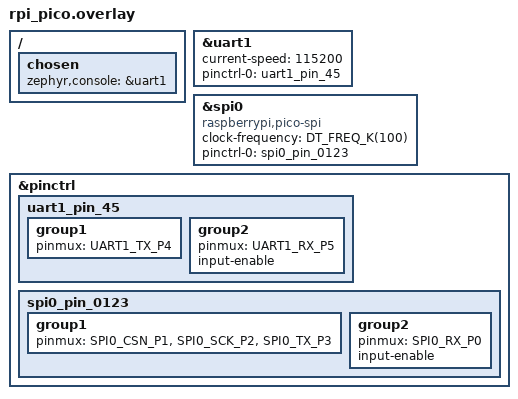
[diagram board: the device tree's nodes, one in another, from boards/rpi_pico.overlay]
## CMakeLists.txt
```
cmake_minimum_required(VERSION 3.20.0)
find_package(Zephyr REQUIRED HINTS $ENV{ZEPHYR_BASE})
project(Car_OS_Zephyr)


set(CMAKE_VERBOSE_MAKEFILE TRUE)

# The default app target from Zephyr
target_sources(app PRIVATE src/main.c)



include(${CMAKE_CURRENT_SOURCE_DIR}/car-os/path_defs.cmake)
#######################################################################################################
# Implementation as per the link below:
# https://github.com/zephyrproject-rtos/zephyr/tree/main/samples/application_development/external_lib
#######################################################################################################
# The external static library that we are linking with (i.e., libCar_OS) does not know how to build for
# this platform. So we export all the flags used in this zephyr build to the external build system.
#
# Other external build systems may be self-contained enough that they do not need any build information
# from zephyr. Or they may be incompatible with certain zephyr options and need them to be filtered out
zephyr_get_include_directories_for_lang_as_string(
  C includes
)
zephyr_get_system_include_directories_for_lang_as_string(
  C system_includes
)
zephyr_get_compile_definitions_for_lang_as_string(
  C definitions
)
zephyr_get_compile_options_for_lang_as_string(
  C options
)

set(
  external_project_cflags
  "${includes} ${definitions} ${options} ${system_includes}"
)

include(ExternalProject)


# Add an external project to be able download and build the third
# party library. In this case downloading is not necessary as it has
# been committed to the repository.
set(CAR_OS_SRC_DIR   ${CMAKE_CURRENT_SOURCE_DIR}/car-os)
set(CAR_OS_BUILD_DIR ${CMAKE_CURRENT_BINARY_DIR}/car-os)
set(CAR_OS_INCLUDE_DIR ${CAR_OS_SRC_DIR}/include)

if(CMAKE_GENERATOR STREQUAL "Unix Makefiles")
  # https://www.gnu.org/software/make/manual/html_node/MAKE-Variable.html
  set(submake "$(MAKE)")
else() # Obviously no MAKEFLAGS. Let's hope a "make" can be found somewhere.
  set(submake "make")
endif()


ExternalProject_Add(
  Car_OS_project                 # Name for custom target
  PREFIX     ${CAR_OS_BUILD_DIR} # Root dir for entire project
  SOURCE_DIR ${CAR_OS_SRC_DIR}
  BINARY_DIR ${CAR_OS_SRC_DIR}   # This particular build system is invoked from the root
  CONFIGURE_COMMAND ""           # Skip configuring the project, e.g. with autoconf
  BUILD_COMMAND ${submake}
  PREFIX=${CAR_OS_BUILD_DIR}
  CC=${CMAKE_C_COMPILER}
  AR=${CMAKE_AR}
  CFLAGS=${external_project_cflags}
  INSTALL_COMMAND ""             # This particular build system has no install command
  BUILD_BYPRODUCTS ${CAR_OS_BASE_DIR_PATH}/libCar_OS.a
  DEPENDS zephyr_interface
)


# Create a wrapper CMake library that our app can link with
add_library(Car_OS_lib STATIC IMPORTED GLOBAL)
add_dependencies(
  Car_OS_lib
  Car_OS_project
)
set_target_properties(Car_OS_lib PROPERTIES IMPORTED_LOCATION             ${CAR_OS_BASE_DIR_PATH}/libCar_OS.a)
set_target_properties(Car_OS_lib PROPERTIES INTERFACE_INCLUDE_DIRECTORIES ${CAR_OS_INCLUDE_DIR})

target_link_libraries(app PUBLIC Car_OS_lib)
target_include_directories(app PUBLIC
  ${CAR_OS_BOARDSOC_PATH}
  ${CAR_OS_INCLUDE_DIR}/autosar
  ${CAR_OS_INCLUDE_DIR}/car_os
  ${CAR_OS_SYSGEN_S_PATH}
  ${CAR_OS_ASR_SRVC_PATH}/Os/include
  ${CAR_OS_ASR_SRVC_PATH}/EcuM/api
  ${CAR_OS_ASR_MCAL_PATH}/Dio/api
)

message(STATUS "Added Car-OS project's makefile to the CMake list.")
```

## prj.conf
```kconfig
# Enable GPIO for LED
CONFIG_GPIO=y


# Logging - refer zephyrproject: samples/subsys/usb/console
# =======
CONFIG_LOG=y
CONFIG_LOG_BUFFER_SIZE=16384


# # Logging over UART
# #------------------
CONFIG_LOG_BACKEND_UART=y
CONFIG_UART_CONSOLE=y
CONFIG_LOG_BACKEND_RTT=n



# Configs while integrating threads
# #-----------------
CONFIG_THREAD_MONITOR=y



# SPI integration
# #-----------------
CONFIG_SPI=y
```

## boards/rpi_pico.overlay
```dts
// Use USB CDC as console output.
// Check out the docs: https://docs.zephyrproject.org/latest/services/usb/uds_cdc_acm.html#console-over-cdc-acm-uart


#include "../car-os/submodules/MCAL/Port/cfg/Port.dtsi"

/ {
	chosen {
		zephyr,console = &uart1;
	};
};

&uart1 {
	current-speed = <115200>;
	status = "okay";
	pinctrl-0 = <&uart1_pin_45>;
	pinctrl-names = "default";
};

&spi0 {
	clock-frequency = <DT_FREQ_K(100)>; /* TODO: Step up the freq to 1 to 10 MHz, ref page 88 of enc. datasheet */
	status = "okay";
	pinctrl-0 = <&spi0_pin_0123>;
	pinctrl-names = "default";
	compatible = "raspberrypi,pico-spi", "arm,pl022";
};

&pinctrl {
	uart1_pin_45: uart1_pin_45 {
		group1 {
			pinmux = <UART1_TX_P4>;
		};
		group2 {
			pinmux = <UART1_RX_P5>;
			input-enable;
		};
	};

	spi0_pin_0123: spi0_pin_0123 {
		group1 {
			pinmux = <SPI0_CSN_P1>, <SPI0_SCK_P2>, <SPI0_TX_P3>;
		};
		group2 {
			pinmux = <SPI0_RX_P0>;
			input-enable;
		};
	};
};
```

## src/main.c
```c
#include <zephyr/kernel.h>
#include <zephyr/logging/log.h>
#include <zephyr/logging/log_ctrl.h>

#include <stdio.h>

#include <osek.h>
#include <os_api.h>
#include <sg_appmodes.h> /* os_builder generated code */

#include <EcuM.h>
#include <Dio.h>




///////////////////////////////////////////////////////////////////////////////
// Macros
#define OS_TICK_MS	(1) /* ms per tick */
#define LED_ONTIME_MS	(250)

#define CAR_OS_COLOR	"\x1B[92m"
#define DEFAULTCOLOR	"\x1B[0m"


///////////////////////////////////////////////////////////////////////////////
// Globals
static struct k_timer OsTickTimer;

LOG_MODULE_REGISTER(Car_OS, LOG_LEVEL_DBG);



///////////////////////////////////////////////////////////////////////////////
// Functions
static void os_ticks(struct k_timer *timer)
{
	static int count = (LED_ONTIME_MS/OS_TICK_MS);

	_OsHandleTicks(); // every 1 ms

	if (--count == 0) {
		Dio_FlipChannel(25); // Main LED is at GPIO25
		count = (LED_ONTIME_MS/OS_TICK_MS);
	}
}


int main(void)
{
        /* Setup logging */
        LOG_INIT();

        /* Car-OS's startup banner */
	LOG_RAW("%sStarting Aananth's Car-OS.Zephyr...%s\n", CAR_OS_COLOR, DEFAULTCOLOR);

	/* AUTOSAR's first function to execute before running OS */
	EcuM_Init(); // TODO: Try to call Call EcuM_Init() much earlier from assembly code.

	/* Setup Car-OS Tick events */
	k_timer_init(&OsTickTimer, os_ticks, NULL);
	k_timer_start(&OsTickTimer, K_MSEC(OS_TICK_MS), K_MSEC(OS_TICK_MS)); // every 1 ms

	/* Start Car-OS, calling a non-returning function */
	StartOS(OSDEFAULTAPPMODE);

	/* The execution should never reach here */
	LOG_ERR("ERROR: AUTOSAR OS exited! The execution will be trapped!");

	/* Loop for ever till restart */
	while (1) {
		k_msleep(5000);
	}

	return 0;
}
```
